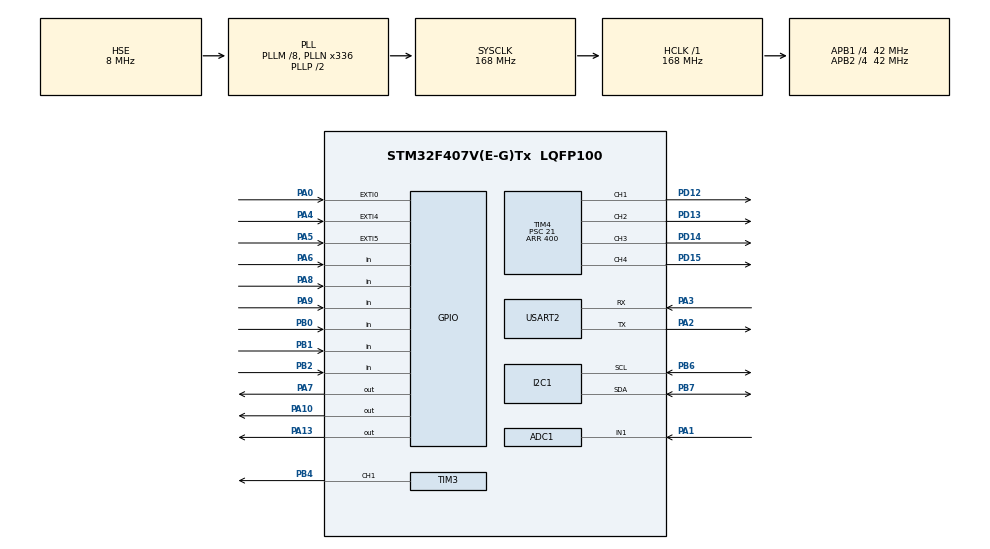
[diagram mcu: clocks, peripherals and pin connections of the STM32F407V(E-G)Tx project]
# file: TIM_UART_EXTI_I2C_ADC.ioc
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ADC1.Channel-0\#ChannelRegularConversion=ADC_CHANNEL_1
ADC1.ClockPrescaler=ADC_CLOCK_SYNC_PCLK_DIV2
ADC1.ContinuousConvMode=DISABLE
ADC1.DMAContinuousRequests=DISABLE
ADC1.DataAlign=ADC_DATAALIGN_RIGHT
ADC1.DiscontinuousConvMode=DISABLE
ADC1.EOCSelection=ADC_EOC_SINGLE_CONV
ADC1.EnableAnalogWatchDog=false
ADC1.ExternalTrigConvEdge=ADC_EXTERNALTRIGCONVEDGE_NONE
ADC1.InjNumberOfConversion=0
ADC1.NbrOfConversion=1
ADC1.NbrOfConversionFlag=1
ADC1.Rank-0\#ChannelRegularConversion=1
ADC1.Resolution=ADC_RESOLUTION_12B
ADC1.SamplingTime-0\#ChannelRegularConversion=ADC_SAMPLETIME_480CYCLES
ADC1.ScanConvMode=DISABLE
ADC1.master=1
Dma.I2C1_RX.1.Channel=DMA_CHANNEL_1
Dma.I2C1_RX.1.Direction=DMA_PERIPH_TO_MEMORY
Dma.I2C1_RX.1.FIFOMode=DMA_FIFOMODE_DISABLE
Dma.I2C1_RX.1.Instance=DMA1_Stream0
Dma.I2C1_RX.1.MemDataAlignment=DMA_MDATAALIGN_BYTE
Dma.I2C1_RX.1.MemInc=DMA_MINC_ENABLE
Dma.I2C1_RX.1.Mode=DMA_CIRCULAR
Dma.I2C1_RX.1.PeriphDataAlignment=DMA_PDATAALIGN_BYTE
Dma.I2C1_RX.1.PeriphInc=DMA_PINC_DISABLE
Dma.I2C1_RX.1.Priority=DMA_PRIORITY_LOW
Dma.Request0=USART2_RX
Dma.Request1=I2C1_RX
Dma.USART2_RX.0.Channel=DMA_CHANNEL_4
Dma.USART2_RX.0.Direction=DMA_PERIPH_TO_MEMORY
Dma.USART2_RX.0.FIFOMode=DMA_FIFOMODE_DISABLE
Dma.USART2_RX.0.Instance=DMA1_Stream5
Dma.USART2_RX.0.MemDataAlignment=DMA_MDATAALIGN_BYTE
Dma.USART2_RX.0.MemInc=DMA_MINC_ENABLE
Dma.USART2_RX.0.Mode=DMA_CIRCULAR
Dma.USART2_RX.0.PeriphDataAlignment=DMA_PDATAALIGN_BYTE
Dma.USART2_RX.0.PeriphInc=DMA_PINC_DISABLE
Dma.USART2_RX.0.Priority=DMA_PRIORITY_LOW
I2C1.I2C_Mode=I2C_Standard
Mcu.Family=STM32F4
Mcu.Name=STM32F407V(E-G)Tx
Mcu.Package=LQFP100
NVIC.ADC_IRQn=true\:0\:0\:false\:false\:true
NVIC.DMA1_Stream0_IRQn=true\:0\:0\:false\:false\:true
NVIC.DMA1_Stream5_IRQn=true\:0\:0\:false\:false\:true
NVIC.EXTI0_IRQn=true\:0\:0\:true\:false\:true
NVIC.EXTI4_IRQn=true\:1\:0\:true\:false\:true
NVIC.EXTI9_5_IRQn=true\:0\:0\:false\:false\:true
NVIC.I2C1_ER_IRQn=true\:0\:0\:false\:false\:true
NVIC.I2C1_EV_IRQn=true\:4\:0\:true\:false\:true
NVIC.PriorityGroup=NVIC_PRIORITYGROUP_4
NVIC.TIM2_IRQn=true\:2\:0\:true\:false\:true
NVIC.USART2_IRQn=true\:5\:0\:true\:false\:true
PA0-WKUP.GPIO_ModeDefaultEXTI=GPIO_MODE_IT_RISING
PA0-WKUP.Signal=GPXTI0
PA1.Signal=ADCx_IN1
PA10.GPIO_PuPd=GPIO_PULLDOWN
PA10.GPIO_Speed=GPIO_SPEED_FREQ_VERY_HIGH
PA10.PinState=GPIO_PIN_RESET
PA10.Signal=GPIO_Output
PA13.GPIO_PuPd=GPIO_PULLDOWN
PA13.GPIO_Speed=GPIO_SPEED_FREQ_VERY_HIGH
PA13.Signal=GPIO_Output
PA2.Mode=Asynchronous
PA2.Signal=USART2_TX
PA3.Mode=Asynchronous
PA3.Signal=USART2_RX
PA4.GPIO_PuPd=GPIO_PULLDOWN
PA4.Signal=GPXTI4
PA5.GPIO_PuPd=GPIO_PULLDOWN
PA5.Signal=GPXTI5
PA6.GPIO_PuPd=GPIO_PULLDOWN
PA6.Signal=GPIO_Input
PA7.GPIO_PuPd=GPIO_PULLDOWN
PA7.GPIO_Speed=GPIO_SPEED_FREQ_VERY_HIGH
PA7.Signal=GPIO_Output
PA8.GPIO_PuPd=GPIO_PULLDOWN
PA8.Signal=GPIO_Input
PA9.GPIO_PuPd=GPIO_PULLDOWN
PA9.Signal=GPIO_Input
PB0.GPIO_PuPd=GPIO_PULLDOWN
PB0.Signal=GPIO_Input
PB1.GPIO_PuPd=GPIO_PULLDOWN
PB1.Signal=GPIO_Input
PB2.GPIO_PuPd=GPIO_PULLDOWN
PB2.Signal=GPIO_Input
PB4.GPIO_Speed=GPIO_SPEED_FREQ_VERY_HIGH
PB4.Signal=S_TIM3_CH1
PB6.Mode=I2C
PB6.Signal=I2C1_SCL
PB7.Mode=I2C
PB7.Signal=I2C1_SDA
PD12.GPIO_ModeDefaultPP=GPIO_MODE_AF_PP
PD12.GPIO_PuPd=GPIO_NOPULL
PD12.GPIO_Speed=GPIO_SPEED_FREQ_VERY_HIGH
PD12.Signal=S_TIM4_CH1
PD13.GPIO_ModeDefaultPP=GPIO_MODE_AF_PP
PD13.GPIO_PuPd=GPIO_NOPULL
PD13.GPIO_Speed=GPIO_SPEED_FREQ_VERY_HIGH
PD13.Signal=S_TIM4_CH2
PD14.GPIO_ModeDefaultPP=GPIO_MODE_AF_PP
PD14.GPIO_PuPd=GPIO_NOPULL
PD14.GPIO_Speed=GPIO_SPEED_FREQ_VERY_HIGH
PD14.Signal=S_TIM4_CH3
PD15.GPIO_Speed=GPIO_SPEED_FREQ_VERY_HIGH
PD15.Signal=S_TIM4_CH4
PH0-OSC_IN.Mode=HSE-External-Oscillator
PH0-OSC_IN.Signal=RCC_OSC_IN
PH1-OSC_OUT.Mode=HSE-External-Oscillator
PH1-OSC_OUT.Signal=RCC_OSC_OUT
ProjectManager.HeapSize=0x200
ProjectManager.StackSize=0x400
ProjectManager.TargetToolchain=MDK-ARM V5
RCC.48MHZClocksFreq_Value=84000000
RCC.AHBFreq_Value=168000000
RCC.APB1CLKDivider=RCC_HCLK_DIV4
RCC.APB1Freq_Value=42000000
RCC.APB1TimFreq_Value=84000000
RCC.APB2CLKDivider=RCC_HCLK_DIV4
RCC.APB2Freq_Value=42000000
RCC.APB2TimFreq_Value=84000000
RCC.CortexFreq_Value=168000000
RCC.HCLKFreq_Value=168000000
RCC.HSE_VALUE=8000000
RCC.HSI_VALUE=16000000
RCC.LSE_VALUE=32768
RCC.PLLM=8
RCC.PLLN=336
RCC.PLLSourceVirtual=RCC_PLLSOURCE_HSE
RCC.SYSCLKFreq_VALUE=168000000
RCC.SYSCLKSource=RCC_SYSCLKSOURCE_PLLCLK
RCC.VCOOutputFreq_Value=336000000
SH.ADCx_IN1.0=ADC1_IN1,IN1
SH.S_TIM3_CH1.0=TIM3_CH1,PWM Generation1 CH1
SH.S_TIM4_CH1.0=TIM4_CH1,PWM Generation1 CH1
SH.S_TIM4_CH2.0=TIM4_CH2,PWM Generation2 CH2
SH.S_TIM4_CH3.0=TIM4_CH3,PWM Generation3 CH3
SH.S_TIM4_CH4.0=TIM4_CH4,PWM Generation4 CH4
TIM2.Period=1999
TIM2.Prescaler=42000
TIM3.Period=400
TIM3.Prescaler=21
TIM4.Channel-PWM\ Generation2\ CH2=TIM_CHANNEL_2
TIM4.Channel-PWM\ Generation3\ CH3=TIM_CHANNEL_3
TIM4.Channel-PWM\ Generation4\ CH4=TIM_CHANNEL_4
TIM4.Period=400
TIM4.Prescaler=21
VP_TIM2_VS_ClockSourceINT.Mode=Internal
VP_TIM3_VS_ClockSourceINT.Mode=Internal
VP_TIM4_VS_ClockSourceINT.Mode=Internal
board=TIM_UART_EXTI_I2C_ADC

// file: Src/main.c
/**
  ******************************************************************************
  * File Name          : main.c
  * Description        : Main program body
  ******************************************************************************
  *
  * COPYRIGHT(c) 2019 STMicroelectronics
  *
  * Redistribution and use in source and binary forms, with or without modification,
  * are permitted provided that the following conditions are met:
  *   1. Redistributions of source code must retain the above copyright notice,
  *      this list of conditions and the following disclaimer.
  *   2. Redistributions in binary form must reproduce the above copyright notice,
  *      this list of conditions and the following disclaimer in the documentation
  *      and/or other materials provided with the distribution.
  *   3. Neither the name of STMicroelectronics nor the names of its contributors
  *      may be used to endorse or promote products derived from this software
  *      without specific prior written permission.
  *
  * THIS SOFTWARE IS PROVIDED BY THE COPYRIGHT HOLDERS AND CONTRIBUTORS "AS IS"
  * AND ANY EXPRESS OR IMPLIED WARRANTIES, INCLUDING, BUT NOT LIMITED TO, THE
  * IMPLIED WARRANTIES OF MERCHANTABILITY AND FITNESS FOR A PARTICULAR PURPOSE ARE
  * DISCLAIMED. IN NO EVENT SHALL THE COPYRIGHT HOLDER OR CONTRIBUTORS BE LIABLE
  * FOR ANY DIRECT, INDIRECT, INCIDENTAL, SPECIAL, EXEMPLARY, OR CONSEQUENTIAL
  * DAMAGES (INCLUDING, BUT NOT LIMITED TO, PROCUREMENT OF SUBSTITUTE GOODS OR
  * SERVICES; LOSS OF USE, DATA, OR PROFITS; OR BUSINESS INTERRUPTION) HOWEVER
  * CAUSED AND ON ANY THEORY OF LIABILITY, WHETHER IN CONTRACT, STRICT LIABILITY,
  * OR TORT (INCLUDING NEGLIGENCE OR OTHERWISE) ARISING IN ANY WAY OUT OF THE USE
  * OF THIS SOFTWARE, EVEN IF ADVISED OF THE POSSIBILITY OF SUCH DAMAGE.
  *
  ******************************************************************************
  */
#include "stm32f4xx_hal.h"

ADC_HandleTypeDef hadc1;

I2C_HandleTypeDef hi2c1;
DMA_HandleTypeDef hdma_i2c1_rx;

TIM_HandleTypeDef htim2;
TIM_HandleTypeDef htim3;
TIM_HandleTypeDef htim4;

UART_HandleTypeDef huart2;
DMA_HandleTypeDef hdma_usart2_rx;

/* USER CODE BEGIN PV */
/* Private variables ---------------------------------------------------------*/
uint8_t a;
/* USER CODE END PV */

void SystemClock_Config(void);
static void MX_GPIO_Init(void);
static void MX_DMA_Init(void);
static void MX_TIM4_Init(void);
static void MX_USART2_UART_Init(void);
static void MX_I2C1_Init(void);
static void MX_ADC1_Init(void);
static void MX_TIM2_Init(void);
static void MX_TIM3_Init(void);

void HAL_TIM_MspPostInit(TIM_HandleTypeDef *htim);

/* USER CODE BEGIN PFP */
/* Private function prototypes -----------------------------------------------*/

/* USER CODE END PFP */

int main(void)
{

  /* MCU Configuration----------------------------------------------------------*/

  /* Reset of all peripherals, Initializes the Flash interface and the Systick. */
  HAL_Init();

  /* Configure the system clock */
  SystemClock_Config();

  /* Initialize all configured peripherals */
  MX_GPIO_Init();
  MX_DMA_Init();
  MX_TIM4_Init();
  MX_USART2_UART_Init();
  MX_I2C1_Init();
  MX_ADC1_Init();
  MX_TIM2_Init();
  MX_TIM3_Init();

  /* Infinite loop */
  while (1)
  {
HAL_Delay(1000);
		a++;
  }

}

/** System Clock Configuration
*/
void SystemClock_Config(void)
{

  RCC_OscInitTypeDef RCC_OscInitStruct;
  RCC_ClkInitTypeDef RCC_ClkInitStruct;

  __HAL_RCC_PWR_CLK_ENABLE();

  __HAL_PWR_VOLTAGESCALING_CONFIG(PWR_REGULATOR_VOLTAGE_SCALE1);

  RCC_OscInitStruct.OscillatorType = RCC_OSCILLATORTYPE_HSE;
  RCC_OscInitStruct.HSEState = RCC_HSE_ON;
  RCC_OscInitStruct.PLL.PLLState = RCC_PLL_ON;
  RCC_OscInitStruct.PLL.PLLSource = RCC_PLLSOURCE_HSE;
  RCC_OscInitStruct.PLL.PLLM = 8;
  RCC_OscInitStruct.PLL.PLLN = 336;
  RCC_OscInitStruct.PLL.PLLP = RCC_PLLP_DIV2;
  RCC_OscInitStruct.PLL.PLLQ = 4;
  HAL_RCC_OscConfig(&RCC_OscInitStruct);

  RCC_ClkInitStruct.ClockType = RCC_CLOCKTYPE_HCLK|RCC_CLOCKTYPE_SYSCLK
                              |RCC_CLOCKTYPE_PCLK1|RCC_CLOCKTYPE_PCLK2;
  RCC_ClkInitStruct.SYSCLKSource = RCC_SYSCLKSOURCE_PLLCLK;
  RCC_ClkInitStruct.AHBCLKDivider = RCC_SYSCLK_DIV1;
  RCC_ClkInitStruct.APB1CLKDivider = RCC_HCLK_DIV4;
  RCC_ClkInitStruct.APB2CLKDivider = RCC_HCLK_DIV4;
  HAL_RCC_ClockConfig(&RCC_ClkInitStruct, FLASH_LATENCY_5);

  HAL_SYSTICK_Config(HAL_RCC_GetHCLKFreq()/1000);

  HAL_SYSTICK_CLKSourceConfig(SYSTICK_CLKSOURCE_HCLK);

  /* SysTick_IRQn interrupt configuration */
  HAL_NVIC_SetPriority(SysTick_IRQn, 0, 0);
}

/* ADC1 init function */
void MX_ADC1_Init(void)
{

  ADC_ChannelConfTypeDef sConfig;

    /**Configure the global features of the ADC (Clock, Resolution, Data Alignment and number of conversion)
    */
  hadc1.Instance = ADC1;
  hadc1.Init.ClockPrescaler = ADC_CLOCK_SYNC_PCLK_DIV2;
  hadc1.Init.Resolution = ADC_RESOLUTION_12B;
  hadc1.Init.ScanConvMode = DISABLE;
  hadc1.Init.ContinuousConvMode = DISABLE;
  hadc1.Init.DiscontinuousConvMode = DISABLE;
  hadc1.Init.ExternalTrigConvEdge = ADC_EXTERNALTRIGCONVEDGE_NONE;
  hadc1.Init.DataAlign = ADC_DATAALIGN_RIGHT;
  hadc1.Init.NbrOfConversion = 1;
  hadc1.Init.DMAContinuousRequests = DISABLE;
  hadc1.Init.EOCSelection = ADC_EOC_SINGLE_CONV;
  HAL_ADC_Init(&hadc1);

    /**Configure for the selected ADC regular channel its corresponding rank in the sequencer and its sample time.
    */
  sConfig.Channel = ADC_CHANNEL_1;
  sConfig.Rank = 1;
  sConfig.SamplingTime = ADC_SAMPLETIME_480CYCLES;
  HAL_ADC_ConfigChannel(&hadc1, &sConfig);

}

/* I2C1 init function */
void MX_I2C1_Init(void)
{

  hi2c1.Instance = I2C1;
  hi2c1.Init.ClockSpeed = 100000;
  hi2c1.Init.DutyCycle = I2C_DUTYCYCLE_2;
  hi2c1.Init.OwnAddress1 = 0;
  hi2c1.Init.AddressingMode = I2C_ADDRESSINGMODE_7BIT;
  hi2c1.Init.DualAddressMode = I2C_DUALADDRESS_DISABLE;
  hi2c1.Init.OwnAddress2 = 0;
  hi2c1.Init.GeneralCallMode = I2C_GENERALCALL_DISABLE;
  hi2c1.Init.NoStretchMode = I2C_NOSTRETCH_DISABLE;
  HAL_I2C_Init(&hi2c1);

}

/* TIM2 init function */
void MX_TIM2_Init(void)
{

  TIM_ClockConfigTypeDef sClockSourceConfig;
  TIM_MasterConfigTypeDef sMasterConfig;

  htim2.Instance = TIM2;
  htim2.Init.Prescaler = 42000;
  htim2.Init.CounterMode = TIM_COUNTERMODE_UP;
  htim2.Init.Period = 1999;
  htim2.Init.ClockDivision = TIM_CLOCKDIVISION_DIV1;
  HAL_TIM_Base_Init(&htim2);

  sClockSourceConfig.ClockSource = TIM_CLOCKSOURCE_INTERNAL;
  HAL_TIM_ConfigClockSource(&htim2, &sClockSourceConfig);

  sMasterConfig.MasterOutputTrigger = TIM_TRGO_RESET;
  sMasterConfig.MasterSlaveMode = TIM_MASTERSLAVEMODE_DISABLE;
  HAL_TIMEx_MasterConfigSynchronization(&htim2, &sMasterConfig);

}

/* TIM3 init function */
void MX_TIM3_Init(void)
{

  TIM_ClockConfigTypeDef sClockSourceConfig;
  TIM_MasterConfigTypeDef sMasterConfig;
  TIM_OC_InitTypeDef sConfigOC;

  htim3.Instance = TIM3;
  htim3.Init.Prescaler = 21;
  htim3.Init.CounterMode = TIM_COUNTERMODE_UP;
  htim3.Init.Period = 400;
  htim3.Init.ClockDivision = TIM_CLOCKDIVISION_DIV1;
  HAL_TIM_Base_Init(&htim3);

  sClockSourceConfig.ClockSource = TIM_CLOCKSOURCE_INTERNAL;
  HAL_TIM_ConfigClockSource(&htim3, &sClockSourceConfig);

  HAL_TIM_PWM_Init(&htim3);

  sMasterConfig.MasterOutputTrigger = TIM_TRGO_RESET;
  sMasterConfig.MasterSlaveMode = TIM_MASTERSLAVEMODE_DISABLE;
  HAL_TIMEx_MasterConfigSynchronization(&htim3, &sMasterConfig);

  sConfigOC.OCMode = TIM_OCMODE_PWM1;
  sConfigOC.Pulse = 0;
  sConfigOC.OCPolarity = TIM_OCPOLARITY_HIGH;
  sConfigOC.OCFastMode = TIM_OCFAST_DISABLE;
  HAL_TIM_PWM_ConfigChannel(&htim3, &sConfigOC, TIM_CHANNEL_1);

  HAL_TIM_MspPostInit(&htim3);

}

/* TIM4 init function */
void MX_TIM4_Init(void)
{

  TIM_ClockConfigTypeDef sClockSourceConfig;
  TIM_MasterConfigTypeDef sMasterConfig;
  TIM_OC_InitTypeDef sConfigOC;

  htim4.Instance = TIM4;
  htim4.Init.Prescaler = 21;
  htim4.Init.CounterMode = TIM_COUNTERMODE_UP;
  htim4.Init.Period = 400;
  htim4.Init.ClockDivision = TIM_CLOCKDIVISION_DIV1;
  HAL_TIM_Base_Init(&htim4);

  sClockSourceConfig.ClockSource = TIM_CLOCKSOURCE_INTERNAL;
  HAL_TIM_ConfigClockSource(&htim4, &sClockSourceConfig);

  HAL_TIM_PWM_Init(&htim4);

  sMasterConfig.MasterOutputTrigger = TIM_TRGO_RESET;
  sMasterConfig.MasterSlaveMode = TIM_MASTERSLAVEMODE_DISABLE;
  HAL_TIMEx_MasterConfigSynchronization(&htim4, &sMasterConfig);

  sConfigOC.OCMode = TIM_OCMODE_PWM1;
  sConfigOC.Pulse = 0;
  sConfigOC.OCPolarity = TIM_OCPOLARITY_HIGH;
  sConfigOC.OCFastMode = TIM_OCFAST_DISABLE;
  HAL_TIM_PWM_ConfigChannel(&htim4, &sConfigOC, TIM_CHANNEL_1);

  HAL_TIM_PWM_ConfigChannel(&htim4, &sConfigOC, TIM_CHANNEL_2);

  HAL_TIM_PWM_ConfigChannel(&htim4, &sConfigOC, TIM_CHANNEL_3);

  HAL_TIM_PWM_ConfigChannel(&htim4, &sConfigOC, TIM_CHANNEL_4);

  HAL_TIM_MspPostInit(&htim4);

}

/* USART2 init function */
void MX_USART2_UART_Init(void)
{

  huart2.Instance = USART2;
  huart2.Init.BaudRate = 115200;
  huart2.Init.WordLength = UART_WORDLENGTH_8B;
  huart2.Init.StopBits = UART_STOPBITS_1;
  huart2.Init.Parity = UART_PARITY_NONE;
  huart2.Init.Mode = UART_MODE_TX_RX;
  huart2.Init.HwFlowCtl = UART_HWCONTROL_NONE;
  huart2.Init.OverSampling = UART_OVERSAMPLING_16;
  HAL_UART_Init(&huart2);

}

void MX_DMA_Init(void)
{
  /* DMA controller clock enable */
  __HAL_RCC_DMA1_CLK_ENABLE();

  /* DMA interrupt init */
  /* DMA1_Stream0_IRQn interrupt configuration */
  HAL_NVIC_SetPriority(DMA1_Stream0_IRQn, 0, 0);
  HAL_NVIC_EnableIRQ(DMA1_Stream0_IRQn);
  /* DMA1_Stream5_IRQn interrupt configuration */
  HAL_NVIC_SetPriority(DMA1_Stream5_IRQn, 0, 0);
  HAL_NVIC_EnableIRQ(DMA1_Stream5_IRQn);

}

/** Configure pins as
        * Analog
        * Input
        * Output
        * EVENT_OUT
        * EXTI
*/
void MX_GPIO_Init(void)
{

  GPIO_InitTypeDef GPIO_InitStruct;

  /* GPIO Ports Clock Enable */
  __HAL_RCC_GPIOH_CLK_ENABLE();
  __HAL_RCC_GPIOA_CLK_ENABLE();
  __HAL_RCC_GPIOB_CLK_ENABLE();
  __HAL_RCC_GPIOD_CLK_ENABLE();

  /*Configure GPIO pin : PA0 */
  GPIO_InitStruct.Pin = GPIO_PIN_0;
  GPIO_InitStruct.Mode = GPIO_MODE_IT_RISING;
  GPIO_InitStruct.Pull = GPIO_NOPULL;
  HAL_GPIO_Init(GPIOA, &GPIO_InitStruct);

  /*Configure GPIO pins : PA4 PA5 */
  GPIO_InitStruct.Pin = GPIO_PIN_4|GPIO_PIN_5;
  GPIO_InitStruct.Mode = GPIO_MODE_IT_RISING;
  GPIO_InitStruct.Pull = GPIO_PULLDOWN;
  HAL_GPIO_Init(GPIOA, &GPIO_InitStruct);

  /*Configure GPIO pins : PA6 PA8 PA9 */
  GPIO_InitStruct.Pin = GPIO_PIN_6|GPIO_PIN_8|GPIO_PIN_9;
  GPIO_InitStruct.Mode = GPIO_MODE_INPUT;
  GPIO_InitStruct.Pull = GPIO_PULLDOWN;
  HAL_GPIO_Init(GPIOA, &GPIO_InitStruct);

  /*Configure GPIO pins : PA7 PA10 PA15 */
  GPIO_InitStruct.Pin = GPIO_PIN_7|GPIO_PIN_10|GPIO_PIN_15;
  GPIO_InitStruct.Mode = GPIO_MODE_OUTPUT_PP;
  GPIO_InitStruct.Pull = GPIO_PULLDOWN;
  GPIO_InitStruct.Speed = GPIO_SPEED_FREQ_VERY_HIGH;
  HAL_GPIO_Init(GPIOA, &GPIO_InitStruct);

  /*Configure GPIO pins : PB0 PB1 PB2 */
  GPIO_InitStruct.Pin = GPIO_PIN_0|GPIO_PIN_1|GPIO_PIN_2;
  GPIO_InitStruct.Mode = GPIO_MODE_INPUT;
  GPIO_InitStruct.Pull = GPIO_PULLDOWN;
  HAL_GPIO_Init(GPIOB, &GPIO_InitStruct);

  /*Configure GPIO pin Output Level */
  HAL_GPIO_WritePin(GPIOA, GPIO_PIN_7|GPIO_PIN_10|GPIO_PIN_15, GPIO_PIN_RESET);

  /* EXTI interrupt init*/
  HAL_NVIC_SetPriority(EXTI0_IRQn, 0, 0);
  HAL_NVIC_EnableIRQ(EXTI0_IRQn);

  HAL_NVIC_SetPriority(EXTI4_IRQn, 1, 0);
  HAL_NVIC_EnableIRQ(EXTI4_IRQn);

  HAL_NVIC_SetPriority(EXTI9_5_IRQn, 0, 0);
  HAL_NVIC_EnableIRQ(EXTI9_5_IRQn);

}

/************************ (C) COPYRIGHT STMicroelectronics *****END OF FILE****/
